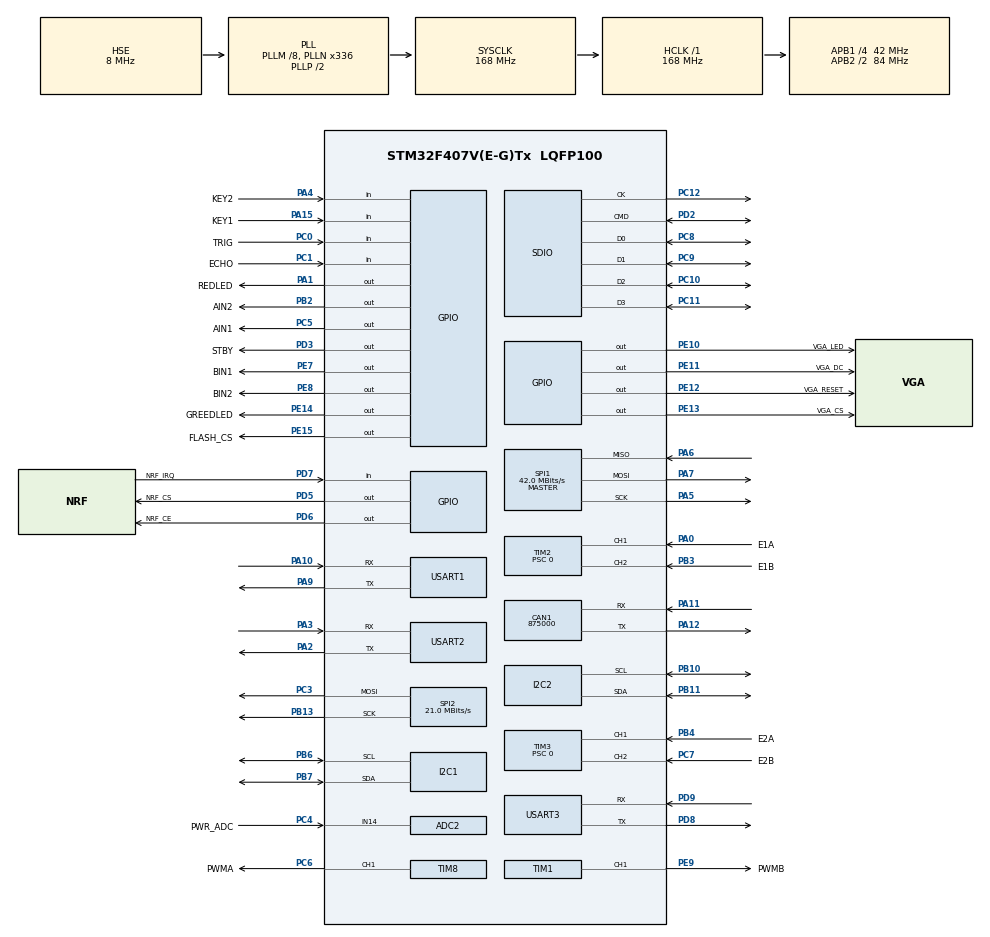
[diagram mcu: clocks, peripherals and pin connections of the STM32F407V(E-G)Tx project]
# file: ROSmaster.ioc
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ADC2.Channel-9\#ChannelRegularConversion=ADC_CHANNEL_14
ADC2.NbrOfConversionFlag=1
ADC2.Rank-9\#ChannelRegularConversion=1
ADC2.SamplingTime-9\#ChannelRegularConversion=ADC_SAMPLETIME_3CYCLES
CAN1.BS1=CAN_BS1_1TQ
CAN1.BS2=CAN_BS2_1TQ
CAN1.CalculateBaudRate=875000
CAN1.CalculateTimeBit=1142
CAN1.CalculateTimeQuantum=380.95238095238096
FREERTOS.BinarySemaphores01=WifiSem,Dynamic,NULL,Available
FREERTOS.Mutexes01=MotorMutex,Dynamic,NULL,Available
FREERTOS.Tasks01=MainTask,0,512,StartMainTask,Default,NULL,Dynamic,NULL,NULL;IMUTask,0,256,StartIMUTask,Default,NULL,Dynamic,NULL,NULL;ShowTask,-1,512,StartShowTask,Default,NULL,Dynamic,NULL,NULL;ControlTask,-1,512,StartControlTask,Default,NULL,Dynamic,NULL,NULL;DataTask,0,512,StartDataTask,Default,NULL,Dynamic,NULL,NULL
FREERTOS.configENABLE_FPU=1
FREERTOS.configUSE_NEWLIB_REENTRANT=1
I2C1.I2C_Mode=I2C_Fast
I2C2.I2C_Mode=I2C_Fast
Mcu.Family=STM32F4
Mcu.Name=STM32F407V(E-G)Tx
Mcu.Package=LQFP100
NVIC.PriorityGroup=NVIC_PRIORITYGROUP_4
NVIC.TIM4_IRQn=true\:15\:0\:false\:false\:true\:false\:false\:true\:true
NVIC.TimeBase=TIM4_IRQn
NVIC.TimeBaseIP=TIM4
NVIC.USART1_IRQn=true\:5\:0\:false\:false\:true\:true\:true\:true\:true
NVIC.USART2_IRQn=true\:5\:0\:false\:false\:true\:true\:true\:true\:true
NVIC.USART3_IRQn=true\:5\:0\:false\:false\:true\:true\:true\:true\:true
PA0-WKUP.GPIO_Label=E1A
PA0-WKUP.GPIO_PuPd=GPIO_PULLUP
PA0-WKUP.Signal=S_TIM2_CH1_ETR
PA1.GPIO_Label=REDLED
PA1.PinState=GPIO_PIN_SET
PA1.Signal=GPIO_Output
PA10.Mode=Asynchronous
PA10.Signal=USART1_RX
PA11.Mode=CAN_Activate
PA11.Signal=CAN1_RX
PA12.Mode=CAN_Activate
PA12.Signal=CAN1_TX
PA13.Mode=Serial_Wire
PA13.Signal=SYS_JTMS-SWDIO
PA14.Mode=Serial_Wire
PA14.Signal=SYS_JTCK-SWCLK
PA15.GPIO_Label=KEY1
PA15.Signal=GPIO_Input
PA2.Mode=Asynchronous
PA2.Signal=USART2_TX
PA3.Mode=Asynchronous
PA3.Signal=USART2_RX
PA4.GPIO_Label=KEY2
PA4.Signal=GPIO_Input
PA5.Mode=Full_Duplex_Master
PA5.Signal=SPI1_SCK
PA6.Mode=Full_Duplex_Master
PA6.Signal=SPI1_MISO
PA7.Mode=Full_Duplex_Master
PA7.Signal=SPI1_MOSI
PA9.Mode=Asynchronous
PA9.Signal=USART1_TX
PB10.Mode=I2C
PB10.Signal=I2C2_SCL
PB11.Mode=I2C
PB11.Signal=I2C2_SDA
PB13.Mode=TX_Only_Simplex_Unidirect_Master
PB13.Signal=SPI2_SCK
PB2.GPIO_Label=AIN2
PB2.Signal=GPIO_Output
PB3.GPIO_Label=E1B
PB3.GPIO_PuPd=GPIO_PULLUP
PB3.Signal=S_TIM2_CH2
PB4.GPIO_Label=E2A
PB4.GPIO_PuPd=GPIO_PULLUP
PB4.Signal=S_TIM3_CH1
PB6.Mode=I2C
PB6.Signal=I2C1_SCL
PB7.Mode=I2C
PB7.Signal=I2C1_SDA
PC0.GPIO_Label=TRIG
PC0.Signal=GPIO_Input
PC1.GPIO_Label=ECHO
PC1.Signal=GPIO_Input
PC10.Mode=SD_4_bits_Wide_bus
PC10.Signal=SDIO_D2
PC11.Mode=SD_4_bits_Wide_bus
PC11.Signal=SDIO_D3
PC12.Mode=SD_4_bits_Wide_bus
PC12.Signal=SDIO_CK
PC3.Mode=TX_Only_Simplex_Unidirect_Master
PC3.Signal=SPI2_MOSI
PC4.GPIO_Label=PWR_ADC
PC4.Signal=ADCx_IN14
PC5.GPIO_Label=AIN1
PC5.Signal=GPIO_Output
PC6.GPIO_Label=PWMA
PC6.Signal=S_TIM8_CH1
PC7.GPIO_Label=E2B
PC7.GPIO_PuPd=GPIO_PULLUP
PC7.Signal=S_TIM3_CH2
PC8.Mode=SD_4_bits_Wide_bus
PC8.Signal=SDIO_D0
PC9.Mode=SD_4_bits_Wide_bus
PC9.Signal=SDIO_D1
PD2.Mode=SD_4_bits_Wide_bus
PD2.Signal=SDIO_CMD
PD3.GPIO_Label=STBY
PD3.Signal=GPIO_Output
PD5.GPIO_Label=NRF_CS
PD5.Signal=GPIO_Output
PD6.GPIO_Label=NRF_CE
PD6.Signal=GPIO_Output
PD7.GPIO_Label=NRF_IRQ
PD7.Signal=GPIO_Input
PD8.Mode=Asynchronous
PD8.Signal=USART3_TX
PD9.Mode=Asynchronous
PD9.Signal=USART3_RX
PE10.GPIO_Label=VGA_LED
PE10.Signal=GPIO_Output
PE11.GPIO_Label=VGA_DC
PE11.Signal=GPIO_Output
PE12.GPIO_Label=VGA_RESET
PE12.Signal=GPIO_Output
PE13.GPIO_Label=VGA_CS
PE13.Signal=GPIO_Output
PE14.GPIO_Label=GREEDLED
PE14.Signal=GPIO_Output
PE15.GPIO_Label=FLASH_CS
PE15.GPIO_PuPd=GPIO_PULLUP
PE15.PinState=GPIO_PIN_SET
PE15.Signal=GPIO_Output
PE7.GPIO_Label=BIN1
PE7.Signal=GPIO_Output
PE8.GPIO_Label=BIN2
PE8.Signal=GPIO_Output
PE9.GPIO_Label=PWMB
PE9.Signal=S_TIM1_CH1
PH0-OSC_IN.Mode=HSE-External-Oscillator
PH0-OSC_IN.Signal=RCC_OSC_IN
PH1-OSC_OUT.Mode=HSE-External-Oscillator
PH1-OSC_OUT.Signal=RCC_OSC_OUT
ProjectManager.HeapSize=0x200
ProjectManager.StackSize=0x400
ProjectManager.TargetToolchain=STM32CubeIDE
RCC.48MHZClocksFreq_Value=48000000
RCC.AHBFreq_Value=168000000
RCC.APB1CLKDivider=RCC_HCLK_DIV4
RCC.APB1Freq_Value=42000000
RCC.APB1TimFreq_Value=84000000
RCC.APB2CLKDivider=RCC_HCLK_DIV2
RCC.APB2Freq_Value=84000000
RCC.APB2TimFreq_Value=168000000
RCC.CortexFreq_Value=168000000
RCC.HCLKFreq_Value=168000000
RCC.HSE_VALUE=8000000
RCC.HSI_VALUE=16000000
RCC.LSE_VALUE=32768
RCC.PLLI2SN=100
RCC.PLLM=8
RCC.PLLN=336
RCC.PLLQ=7
RCC.PLLSourceVirtual=RCC_PLLSOURCE_HSE
RCC.SYSCLKFreq_VALUE=168000000
RCC.SYSCLKSource=RCC_SYSCLKSOURCE_PLLCLK
RCC.VCOOutputFreq_Value=336000000
SH.ADCx_IN14.0=ADC2_IN14,IN14
SH.S_TIM1_CH1.0=TIM1_CH1,PWM Generation1 CH1
SH.S_TIM2_CH1_ETR.0=TIM2_CH1,Encoder_Interface
SH.S_TIM2_CH2.0=TIM2_CH2,Encoder_Interface
SH.S_TIM3_CH1.0=TIM3_CH1,Encoder_Interface
SH.S_TIM3_CH2.0=TIM3_CH2,Encoder_Interface
SH.S_TIM8_CH1.0=TIM8_CH1,PWM Generation1 CH1
SPI1.BaudRatePrescaler=SPI_BAUDRATEPRESCALER_2
SPI1.CalculateBaudRate=42.0 MBits/s
SPI1.Direction=SPI_DIRECTION_2LINES
SPI1.Mode=SPI_MODE_MASTER
SPI1.VirtualType=VM_MASTER
SPI2.BaudRatePrescaler=SPI_BAUDRATEPRESCALER_2
SPI2.CalculateBaudRate=21.0 MBits/s
SPI2.Direction=SPI_DIRECTION_2LINES
SPI2.Mode=SPI_MODE_MASTER
SPI2.VirtualType=VM_MASTER
TIM1.AutoReloadPreload=TIM_AUTORELOAD_PRELOAD_DISABLE
TIM1.Channel-PWM\ Generation1\ CH1=TIM_CHANNEL_1
TIM1.Period=2000-1
TIM1.Prescaler=84-1
TIM2.EncoderMode=TIM_ENCODERMODE_TI12
TIM2.IC1Filter=2
TIM2.Period=60000
TIM2.Prescaler=0
TIM3.EncoderMode=TIM_ENCODERMODE_TI12
TIM3.Period=60000
TIM3.Prescaler=0
TIM8.Channel-PWM\ Generation1\ CH1=TIM_CHANNEL_1
TIM8.Period=2000-1
TIM8.Prescaler=84-1
USART1.VirtualMode=VM_ASYNC
USART2.VirtualMode=VM_ASYNC
USART3.VirtualMode=VM_ASYNC
VP_FATFS_VS_SDIO.Mode=SDIO
VP_FREERTOS_VS_CMSIS_V1.Mode=CMSIS_V1
VP_RTC_VS_RTC_Activate.Mode=RTC_Enabled
VP_SYS_VS_tim4.Mode=TIM4
VP_TIM1_VS_ClockSourceINT.Mode=Internal
VP_TIM8_VS_ClockSourceINT.Mode=Internal
board=custom

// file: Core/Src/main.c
/* USER CODE BEGIN Header */
/**
  ******************************************************************************
  * @file           : main.c
  * @brief          : Main program body
  ******************************************************************************
  * @attention
  *
  * Copyright (c) 2023 STMicroelectronics.
  * All rights reserved.
  *
  * This software is licensed under terms that can be found in the LICENSE file
  * in the root directory of this software component.
  * If no LICENSE file comes with this software, it is provided AS-IS.
  *
  ******************************************************************************
  */
/* USER CODE END Header */
#include "main.h"
#include "cmsis_os.h"
#include "adc.h"
#include "can.h"
#include "fatfs.h"
#include "i2c.h"
#include "rtc.h"
#include "sdio.h"
#include "spi.h"
#include "tim.h"
#include "usart.h"
#include "gpio.h"

void SystemClock_Config(void);
void MX_FREERTOS_Init(void);

int main(void)
{

  /* MCU Configuration--------------------------------------------------------*/

  /* Reset of all peripherals, Initializes the Flash interface and the Systick. */
  HAL_Init();

  /* Configure the system clock */
  SystemClock_Config();

  /* Initialize all configured peripherals */
  MX_GPIO_Init();
  MX_USART1_UART_Init();
  MX_I2C1_Init();
  MX_SDIO_SD_Init();
  MX_FATFS_Init();
  MX_SPI1_Init();
  MX_RTC_Init();
  MX_CAN1_Init();
  MX_USART2_UART_Init();
  MX_I2C2_Init();
  MX_USART3_UART_Init();
  MX_TIM1_Init();
  MX_TIM2_Init();
  MX_TIM3_Init();
  MX_ADC2_Init();
  MX_SPI2_Init();
  MX_TIM8_Init();

  /* Call init function for freertos objects (in cmsis_os2.c) */
  MX_FREERTOS_Init();

  /* Start scheduler */
  osKernelStart();

  /* We should never get here as control is now taken by the scheduler */

  /* Infinite loop */
  while (1)
  {

  }
}

void SystemClock_Config(void)
{
  RCC_OscInitTypeDef RCC_OscInitStruct = {0};
  RCC_ClkInitTypeDef RCC_ClkInitStruct = {0};

  /** Configure the main internal regulator output voltage
  */
  __HAL_RCC_PWR_CLK_ENABLE();
  __HAL_PWR_VOLTAGESCALING_CONFIG(PWR_REGULATOR_VOLTAGE_SCALE1);

  /** Initializes the RCC Oscillators according to the specified parameters
  * in the RCC_OscInitTypeDef structure.
  */
  RCC_OscInitStruct.OscillatorType = RCC_OSCILLATORTYPE_LSI|RCC_OSCILLATORTYPE_HSE;
  RCC_OscInitStruct.HSEState = RCC_HSE_ON;
  RCC_OscInitStruct.LSIState = RCC_LSI_ON;
  RCC_OscInitStruct.PLL.PLLState = RCC_PLL_ON;
  RCC_OscInitStruct.PLL.PLLSource = RCC_PLLSOURCE_HSE;
  RCC_OscInitStruct.PLL.PLLM = 8;
  RCC_OscInitStruct.PLL.PLLN = 336;
  RCC_OscInitStruct.PLL.PLLP = RCC_PLLP_DIV2;
  RCC_OscInitStruct.PLL.PLLQ = 7;
  if (HAL_RCC_OscConfig(&RCC_OscInitStruct) != HAL_OK)
  {
    Error_Handler();
  }

  /** Initializes the CPU, AHB and APB buses clocks
  */
  RCC_ClkInitStruct.ClockType = RCC_CLOCKTYPE_HCLK|RCC_CLOCKTYPE_SYSCLK
                              |RCC_CLOCKTYPE_PCLK1|RCC_CLOCKTYPE_PCLK2;
  RCC_ClkInitStruct.SYSCLKSource = RCC_SYSCLKSOURCE_PLLCLK;
  RCC_ClkInitStruct.AHBCLKDivider = RCC_SYSCLK_DIV1;
  RCC_ClkInitStruct.APB1CLKDivider = RCC_HCLK_DIV4;
  RCC_ClkInitStruct.APB2CLKDivider = RCC_HCLK_DIV2;

  if (HAL_RCC_ClockConfig(&RCC_ClkInitStruct, FLASH_LATENCY_5) != HAL_OK)
  {
    Error_Handler();
  }
}

void HAL_TIM_PeriodElapsedCallback(TIM_HandleTypeDef *htim)
{
  if (htim->Instance == TIM4)
  {
    HAL_IncTick();
  }
}

void Error_Handler(void)
{
  __disable_irq();
  while (1)
  {
  }
}

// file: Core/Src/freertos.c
/* USER CODE BEGIN Header */
/**
  ******************************************************************************
  * File Name          : freertos.c
  * Description        : Code for freertos applications
  ******************************************************************************
  * @attention
  *
  * Copyright (c) 2023 STMicroelectronics.
  * All rights reserved.
  *
  * This software is licensed under terms that can be found in the LICENSE file
  * in the root directory of this software component.
  * If no LICENSE file comes with this software, it is provided AS-IS.
  *
  ******************************************************************************
  */
/* USER CODE END Header */

#include "FreeRTOS.h"
#include "task.h"
#include "main.h"
#include "cmsis_os.h"

/* USER CODE BEGIN Includes */
#include "app.h"
/* USER CODE END Includes */

osThreadId MainTaskHandle;
osThreadId IMUTaskHandle;
osThreadId ShowTaskHandle;
osThreadId ControlTaskHandle;
osThreadId DataTaskHandle;
osMutexId MotorMutexHandle;
osSemaphoreId WifiSemHandle;

void StartMainTask(void const * argument);
void StartIMUTask(void const * argument);
void StartShowTask(void const * argument);
void StartControlTask(void const * argument);
void StartDataTask(void const * argument);

void MX_FREERTOS_Init(void); /* (MISRA C 2004 rule 8.1) */

/* GetIdleTaskMemory prototype (linked to static allocation support) */
void vApplicationGetIdleTaskMemory( StaticTask_t **ppxIdleTaskTCBBuffer, StackType_t **ppxIdleTaskStackBuffer, uint32_t *pulIdleTaskStackSize );

/* USER CODE BEGIN GET_IDLE_TASK_MEMORY */
static StaticTask_t xIdleTaskTCBBuffer;
static StackType_t xIdleStack[configMINIMAL_STACK_SIZE];

void vApplicationGetIdleTaskMemory( StaticTask_t **ppxIdleTaskTCBBuffer, StackType_t **ppxIdleTaskStackBuffer, uint32_t *pulIdleTaskStackSize )
{
  *ppxIdleTaskTCBBuffer = &xIdleTaskTCBBuffer;
  *ppxIdleTaskStackBuffer = &xIdleStack[0];
  *pulIdleTaskStackSize = configMINIMAL_STACK_SIZE;
  /* place for user code */
}
/* USER CODE END GET_IDLE_TASK_MEMORY */

void MX_FREERTOS_Init(void) {
  /* USER CODE BEGIN Init */
	App_Init();
  /* USER CODE END Init */
  /* Create the mutex(es) */
  /* definition and creation of MotorMutex */
  osMutexDef(MotorMutex);
  MotorMutexHandle = osMutexCreate(osMutex(MotorMutex));

  /* Create the semaphores(s) */
  /* definition and creation of WifiSem */
  osSemaphoreDef(WifiSem);
  WifiSemHandle = osSemaphoreCreate(osSemaphore(WifiSem), 1);

  /* Create the thread(s) */
  /* definition and creation of MainTask */
  osThreadDef(MainTask, StartMainTask, osPriorityNormal, 0, 512);
  MainTaskHandle = osThreadCreate(osThread(MainTask), NULL);

  /* definition and creation of IMUTask */
  osThreadDef(IMUTask, StartIMUTask, osPriorityNormal, 0, 256);
  IMUTaskHandle = osThreadCreate(osThread(IMUTask), NULL);

  /* definition and creation of ShowTask */
  osThreadDef(ShowTask, StartShowTask, osPriorityBelowNormal, 0, 512);
  ShowTaskHandle = osThreadCreate(osThread(ShowTask), NULL);

  /* definition and creation of ControlTask */
  osThreadDef(ControlTask, StartControlTask, osPriorityBelowNormal, 0, 512);
  ControlTaskHandle = osThreadCreate(osThread(ControlTask), NULL);

  /* definition and creation of DataTask */
  osThreadDef(DataTask, StartDataTask, osPriorityNormal, 0, 512);
  DataTaskHandle = osThreadCreate(osThread(DataTask), NULL);

}

void StartMainTask(void const * argument)
{
  /* USER CODE BEGIN StartMainTask */

  /* Infinite loop */
  for(;;)
  {
  		App_Balance_Task();
	    osDelay(5);
  }
  /* USER CODE END StartMainTask */
}

void StartIMUTask(void const * argument)
{
  /* USER CODE BEGIN StartIMUTask */
  /* Infinite loop */

  for(;;)
  {
	App_IMU_Task();
    osDelay(1);
  }
  /* USER CODE END StartIMUTask */
}

void StartShowTask(void const * argument)
{
  /* USER CODE BEGIN StartShowTask */
  /* Infinite loop */
  for(;;)
  {
  	App_Show_Task();
    osDelay(100);
  }
  /* USER CODE END StartShowTask */
}

void StartControlTask(void const * argument)
{
  /* USER CODE BEGIN StartControlTask */
  /* Infinite loop */
  for(;;)
  {
  	 App_Control_Task();
     osDelay(5);
  }
  /* USER CODE END StartControlTask */
}

void StartDataTask(void const * argument)
{
  /* USER CODE BEGIN StartDataTask */
  /* Infinite loop */
  for(;;)
  {
  	App_Data_Task();
    osDelay(10);
  }
  /* USER CODE END StartDataTask */
}
